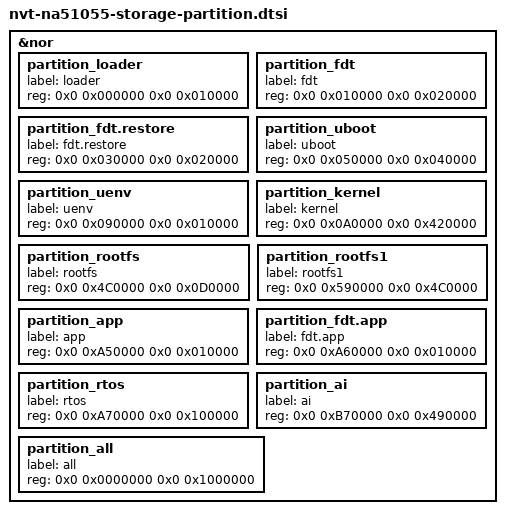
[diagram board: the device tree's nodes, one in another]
/*
 * Novatek Ltd. NA51055 BSP part of dts
 *
 * Cortex-A9
 *
 */

&nor {
	partition_loader {      label = "loader";       reg = <0x0 0x000000  0x0 0x010000>; }; /* Fixed */
	partition_fdt {	        label = "fdt";	        reg = <0x0 0x010000  0x0 0x020000>; }; /* Fixed */
	partition_fdt.restore {	label = "fdt.restore";	reg = <0x0 0x030000  0x0 0x020000>; }; /* Fixed */
	partition_uboot {       label = "uboot";        reg = <0x0 0x050000  0x0 0x040000>; };
	partition_uenv {        label = "uenv";         reg = <0x0 0x090000  0x0 0x010000>; };
	partition_kernel {      label = "kernel";       reg = <0x0 0x0A0000  0x0 0x420000>; };
	partition_rootfs {      label = "rootfs";       reg = <0x0 0x4C0000  0x0 0x0D0000>; };
	partition_rootfs1 {     label = "rootfs1";      reg = <0x0 0x590000  0x0 0x4C0000>; };
	partition_app {         label = "app";          reg = <0x0 0xA50000  0x0 0x010000>; };
	partition_fdt.app {     label = "fdt.app";      reg = <0x0 0xA60000  0x0 0x010000>; };
	partition_rtos {        label = "rtos";         reg = <0x0 0xA70000  0x0 0x100000>; };
	partition_ai {          label = "ai";           reg = <0x0 0xB70000  0x0 0x490000>; };
	partition_all {         label = "all";          reg = <0x0 0x0000000 0x0 0x1000000>; };
};
